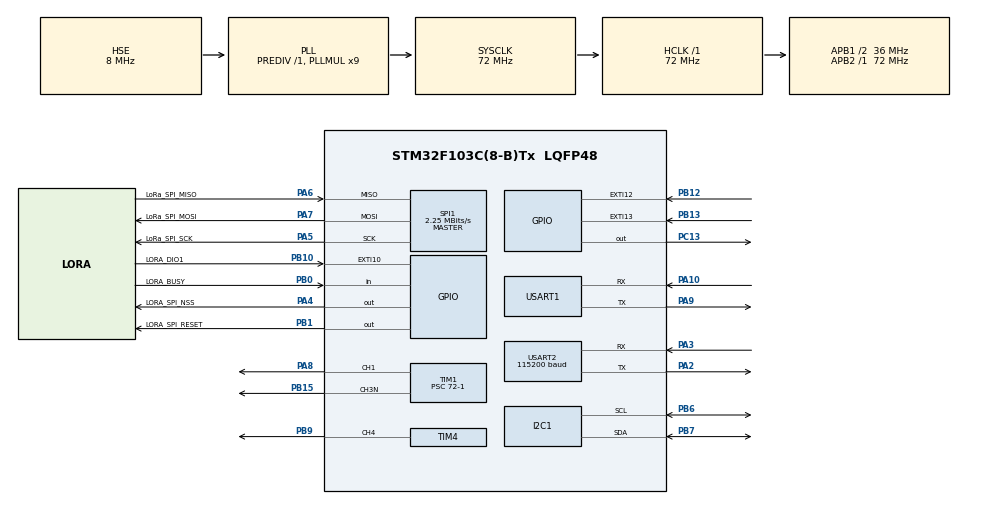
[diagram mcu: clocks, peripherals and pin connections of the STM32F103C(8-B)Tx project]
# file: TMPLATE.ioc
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Mcu.Family=STM32F1
Mcu.Name=STM32F103C(8-B)Tx
Mcu.Package=LQFP48
NVIC.EXTI15_10_IRQn=true\:0\:0\:false\:false\:true\:true\:true\:true
NVIC.PriorityGroup=NVIC_PRIORITYGROUP_4
NVIC.USART1_IRQn=true\:0\:0\:false\:false\:true\:true\:true\:true
NVIC.USART2_IRQn=true\:0\:0\:false\:false\:true\:true\:true\:true
PA10.Mode=Asynchronous
PA10.Signal=USART1_RX
PA13.Mode=Serial_Wire
PA13.Signal=SYS_JTMS-SWDIO
PA14.Mode=Serial_Wire
PA14.Signal=SYS_JTCK-SWCLK
PA2.Mode=Asynchronous
PA2.Signal=USART2_TX
PA3.Mode=Asynchronous
PA3.Signal=USART2_RX
PA4.GPIO_Label=LORA_SPI_NSS
PA4.GPIO_Speed=GPIO_SPEED_FREQ_HIGH
PA4.PinState=GPIO_PIN_SET
PA4.Signal=GPIO_Output
PA5.GPIO_Label=LoRa_SPI_SCK
PA5.Mode=Full_Duplex_Master
PA5.Signal=SPI1_SCK
PA6.GPIO_Label=LoRa_SPI_MISO
PA6.Mode=Full_Duplex_Master
PA6.Signal=SPI1_MISO
PA7.GPIO_Label=LoRa_SPI_MOSI
PA7.Mode=Full_Duplex_Master
PA7.Signal=SPI1_MOSI
PA8.GPIO_Speed=GPIO_SPEED_FREQ_HIGH
PA8.Signal=S_TIM1_CH1
PA9.Mode=Asynchronous
PA9.Signal=USART1_TX
PB0.GPIO_Label=LORA_BUSY
PB0.Signal=GPIO_Input
PB1.GPIO_Label=LORA_SPI_RESET
PB1.GPIO_Speed=GPIO_SPEED_FREQ_HIGH
PB1.PinState=GPIO_PIN_SET
PB1.Signal=GPIO_Output
PB10.GPIO_Label=LORA_DIO1
PB10.Signal=GPXTI10
PB12.GPIO_ModeDefaultEXTI=GPIO_MODE_IT_FALLING
PB12.GPIO_PuPd=GPIO_PULLUP
PB12.Signal=GPXTI12
PB13.GPIO_ModeDefaultEXTI=GPIO_MODE_IT_FALLING
PB13.GPIO_PuPd=GPIO_PULLUP
PB13.Signal=GPXTI13
PB15.GPIO_Speed=GPIO_SPEED_FREQ_HIGH
PB15.Mode=PWM Generation3 CH3N
PB15.Signal=TIM1_CH3N
PB6.Mode=I2C
PB6.Signal=I2C1_SCL
PB7.Mode=I2C
PB7.Signal=I2C1_SDA
PB9.Signal=S_TIM4_CH4
PC13-TAMPER-RTC.Signal=GPIO_Output
PD0-OSC_IN.Mode=HSE-External-Oscillator
PD0-OSC_IN.Signal=RCC_OSC_IN
PD1-OSC_OUT.Mode=HSE-External-Oscillator
PD1-OSC_OUT.Signal=RCC_OSC_OUT
ProjectManager.HeapSize=0x200
ProjectManager.StackSize=0x400
ProjectManager.TargetToolchain=MDK-ARM V5
RCC.ADCPresc=RCC_ADCPCLK2_DIV6
RCC.AHBFreq_Value=72000000
RCC.APB1CLKDivider=RCC_HCLK_DIV2
RCC.APB1Freq_Value=36000000
RCC.APB1TimFreq_Value=72000000
RCC.APB2Freq_Value=72000000
RCC.APB2TimFreq_Value=72000000
RCC.HCLKFreq_Value=72000000
RCC.PLLMUL=RCC_PLL_MUL9
RCC.PLLSourceVirtual=RCC_PLLSOURCE_HSE
RCC.SYSCLKFreq_VALUE=72000000
RCC.SYSCLKSource=RCC_SYSCLKSOURCE_PLLCLK
RCC.USBFreq_Value=72000000
SH.S_TIM1_CH1.0=TIM1_CH1,PWM Generation1 CH1
SH.S_TIM4_CH4.0=TIM4_CH4,PWM Generation4 CH4
SPI1.BaudRatePrescaler=SPI_BAUDRATEPRESCALER_32
SPI1.CalculateBaudRate=2.25 MBits/s
SPI1.Direction=SPI_DIRECTION_2LINES
SPI1.Mode=SPI_MODE_MASTER
SPI1.VirtualType=VM_MASTER
TIM1.AutoReloadPreload=TIM_AUTORELOAD_PRELOAD_ENABLE
TIM1.Channel-PWM\ Generation1\ CH1=TIM_CHANNEL_1
TIM1.Channel-PWM\ Generation3\ CH3N=TIM_CHANNEL_3
TIM1.Period=999
TIM1.Prescaler=72-1
TIM4.AutoReloadPreload=TIM_AUTORELOAD_PRELOAD_ENABLE
TIM4.Channel-PWM\ Generation4\ CH4=TIM_CHANNEL_4
TIM4.Period=332
TIM4.Prescaler=72-1
USART1.VirtualMode=VM_ASYNC
USART2.BaudRate=115200
USART2.VirtualMode=VM_ASYNC
VP_TIM1_VS_ClockSourceINT.Mode=Internal
VP_TIM4_VS_ClockSourceINT.Mode=Internal
board=custom

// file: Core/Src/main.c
/* USER CODE BEGIN Header */
/**
  ******************************************************************************
  * @file           : main.c
  * @brief          : Main program body
  ******************************************************************************
  * @attention
  *
  * Copyright (c) 2026 STMicroelectronics.
  * All rights reserved.
  *
  * This software is licensed under terms that can be found in the LICENSE file
  * in the root directory of this software component.
  * If no LICENSE file comes with this software, it is provided AS-IS.
  *
  ******************************************************************************
  */
/* USER CODE END Header */
#include "main.h"
#include "i2c.h"
#include "spi.h"
#include "tim.h"
#include "usart.h"
#include "gpio.h"

/* USER CODE BEGIN Includes */
/*用户代码区->导入头文件#include "stdio.h"*/
#include "app_main.h"   //app_main() 的声明，不加会报 #223-D 隐式声明警告

/* USER CODE END Includes */

/* USER CODE BEGIN PTD */
/*用户代码区->定义类型（一般使用固定字节数类型，保证64/32都能正常）*/

/* USER CODE END PTD */

/* USER CODE BEGIN PD */
/*用户代码区->定义常量（pi或者其他系数）*/
#define RCC_APB2ENR    (*(unsigned int *)0x40021018)
#define GPIOC_CRH      (*(unsigned int *)0x40011004)
#define GPIOC_ODR      (*(unsigned int *)0x4001100C)

/* USER CODE END PD */

/* USER CODE BEGIN PM */
/*用户代码区->定义宏（可以将常用（高频）代码放入宏，
在预编译阶段插入，受编译器限制）
*/

/* USER CODE END PM */

/* USER CODE BEGIN PV */
//用户代码区->自定义全局变量

/* USER CODE END PV */

void SystemClock_Config(void);
/* USER CODE BEGIN PFP */
/*用户代码区->声明自定义函数（用户定义的私有函数声明）*/

/* USER CODE END PFP */

/* USER CODE BEGIN 0 */
/*这是一个“万能用户代码区”，最常见的是用来放置自定义函数的
实现（函数体）。当然，你也可以在这里定义只在本文件中使用的私有全局变量或宏。
*/

/* USER CODE END 0 */

int main(void)
{

  /* MCU Configuration--------------------------------------------------------*/

  /* Reset of all peripherals, Initializes the Flash interface and the Systick. */
  HAL_Init();

  /* Configure the system clock */
  SystemClock_Config();

  /* USER CODE BEGIN SysInit */
	//gpio_test();

  /* USER CODE END SysInit */

  /* Initialize all configured peripherals */
  MX_GPIO_Init();
  MX_USART1_UART_Init();
  MX_TIM1_Init();
  MX_USART2_UART_Init();
  MX_TIM4_Init();
  MX_I2C1_Init();
  MX_SPI1_Init();

  /* Infinite loop */
  /* USER CODE BEGIN WHILE */

		app_main();

	while (1)
  {

    /* USER CODE END WHILE */

  }
}

void SystemClock_Config(void)
{
  RCC_OscInitTypeDef RCC_OscInitStruct = {0};
  RCC_ClkInitTypeDef RCC_ClkInitStruct = {0};

  /** Initializes the RCC Oscillators according to the specified parameters
  * in the RCC_OscInitTypeDef structure.
  */
  RCC_OscInitStruct.OscillatorType = RCC_OSCILLATORTYPE_HSE;
  RCC_OscInitStruct.HSEState = RCC_HSE_ON;
  RCC_OscInitStruct.HSEPredivValue = RCC_HSE_PREDIV_DIV1;
  RCC_OscInitStruct.HSIState = RCC_HSI_ON;
  RCC_OscInitStruct.PLL.PLLState = RCC_PLL_ON;
  RCC_OscInitStruct.PLL.PLLSource = RCC_PLLSOURCE_HSE;
  RCC_OscInitStruct.PLL.PLLMUL = RCC_PLL_MUL9;
  if (HAL_RCC_OscConfig(&RCC_OscInitStruct) != HAL_OK)
  {
    Error_Handler();
  }

  /** Initializes the CPU, AHB and APB buses clocks
  */
  RCC_ClkInitStruct.ClockType = RCC_CLOCKTYPE_HCLK|RCC_CLOCKTYPE_SYSCLK
                              |RCC_CLOCKTYPE_PCLK1|RCC_CLOCKTYPE_PCLK2;
  RCC_ClkInitStruct.SYSCLKSource = RCC_SYSCLKSOURCE_PLLCLK;
  RCC_ClkInitStruct.AHBCLKDivider = RCC_SYSCLK_DIV1;
  RCC_ClkInitStruct.APB1CLKDivider = RCC_HCLK_DIV2;
  RCC_ClkInitStruct.APB2CLKDivider = RCC_HCLK_DIV1;

  if (HAL_RCC_ClockConfig(&RCC_ClkInitStruct, FLASH_LATENCY_2) != HAL_OK)
  {
    Error_Handler();
  }
}

void Error_Handler(void)
{
  __disable_irq();
  while (1)
  {
  }
}
